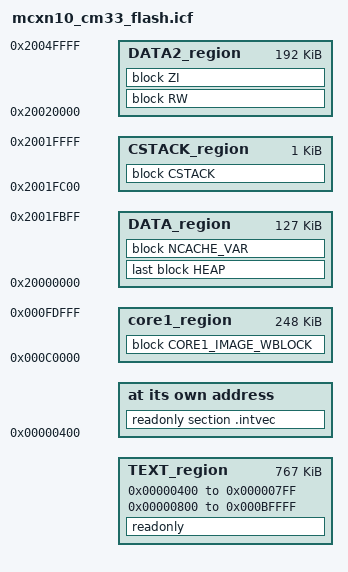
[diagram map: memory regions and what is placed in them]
/*
** ###################################################################
**     Processors:          
**
**     Compiler:            IAR ANSI C/C++ Compiler for ARM
**     Reference manual:    
**     Version:             rev. 0.1, 2018-06-22
**     Build:               b190730
**
**     Abstract:
**         Linker file for the IAR ANSI C/C++ Compiler for ARM
**
**     Copyright 2016 Freescale Semiconductor, Inc.
**     Copyright 2016-2019, 2022 NXP
**     All rights reserved.
**
**     SPDX-License-Identifier: BSD-3-Clause
**
**     http:                 www.nxp.com
**     mail:                 support@nxp.com
**
** ###################################################################
*/

/* Flash range to be used is from 0x0000_0000 to 0x0010_0000
    - the region after is a storage for Candidate application
    - there is 0x400 bytes of the MCU boot header at the beginning of the 1st slot
    - the *core1_image_size* parameter allocates space for core1 image that will be merged
      with the resulting binary before signing
    - at the end of application image there is a reserved area for image trailer
      of size of one flash sector (8 kB)
*/


define symbol mcuboot_header_size      = 0x400;
define symbol mcuboot_trailer_size     = 0x2000;
define symbol interrupts_size          = 0x400;
define symbol core1_image_size         = 0x40000;

define symbol primary_slot_base        = 0x00000000;
define symbol primary_slot_size        = 0x00100000;


define symbol m_interrupts_start       = primary_slot_base + mcuboot_header_size;
define symbol m_interrupts_end         = m_interrupts_start + interrupts_size - 1;

define symbol m_text_start             = primary_slot_base + mcuboot_header_size + interrupts_size;
define symbol m_text_end               = 0x000BFFFF;

define exported symbol core1_image_start   = 0x000C0000;
define exported symbol core1_image_end     = core1_image_start + core1_image_size - mcuboot_trailer_size - 1;

define symbol m_data_start             = 0x20000000;
define symbol m_data_end               = 0x2001FFFF;

define symbol m_data2_start            = 0x20020000;
define symbol m_data2_end              = 0x2004FFFF;




/* Sizes */
if (isdefinedsymbol(__stack_size__)) {
  define symbol __size_cstack__        = __stack_size__;
} else {
  define symbol __size_cstack__        = 0x0400;
}

if (isdefinedsymbol(__heap_size__)) {
  define symbol __size_heap__          = __heap_size__;
} else {
  define symbol __size_heap__          = 0x0400;
}

define exported symbol __NCACHE_REGION_START   = m_data2_start;
define exported symbol __NCACHE_REGION_SIZE    = 0x0;

define exported symbol __VECTOR_TABLE  = m_interrupts_start;
define exported symbol __VECTOR_RAM    = m_interrupts_start;
define exported symbol __RAM_VECTOR_TABLE_SIZE = 0x0;

define memory mem with size = 4G;
define region TEXT_region = mem:[from m_interrupts_start to m_interrupts_end]
                          | mem:[from m_text_start to m_text_end];
define region DATA_region = mem:[from m_data_start to m_data_end-__size_cstack__];
define region DATA2_region = mem:[from m_data2_start to m_data2_end];
define region CSTACK_region = mem:[from m_data_end-__size_cstack__+1 to m_data_end];

define block CSTACK    with alignment = 8, size = __size_cstack__   { };
define block HEAP      with alignment = 8, size = __size_heap__     { };
define block RW        { readwrite };
define block ZI        { zi };
define block NCACHE_VAR    { section NonCacheable , section NonCacheable.init };

define region core1_region = mem:[from core1_image_start to core1_image_end];
define block CORE1_IMAGE_WBLOCK          { section  __core1_image };

initialize by copy {
  readwrite,
  section .textrw,
  object mflash_drv.o
};

do not initialize  { section .noinit };

place at address mem: m_interrupts_start    { readonly section .intvec };

place in TEXT_region                        { readonly };
place in DATA2_region                       { block RW };
place in DATA2_region                       { block ZI };
place in DATA_region                        { last block HEAP };
place in DATA_region                        { block NCACHE_VAR };
place in CSTACK_region                      { block CSTACK };
place in core1_region                       { block CORE1_IMAGE_WBLOCK };

